VERSION ""

NS_ :

BS_:

BU_: Master ODrive_Axis0 ODrive_Axis1 ODrive_Axis2 ODrive_Axis3 ODrive_Axis4 ODrive_Axis5 ODrive_Axis6 ODrive_Axis7

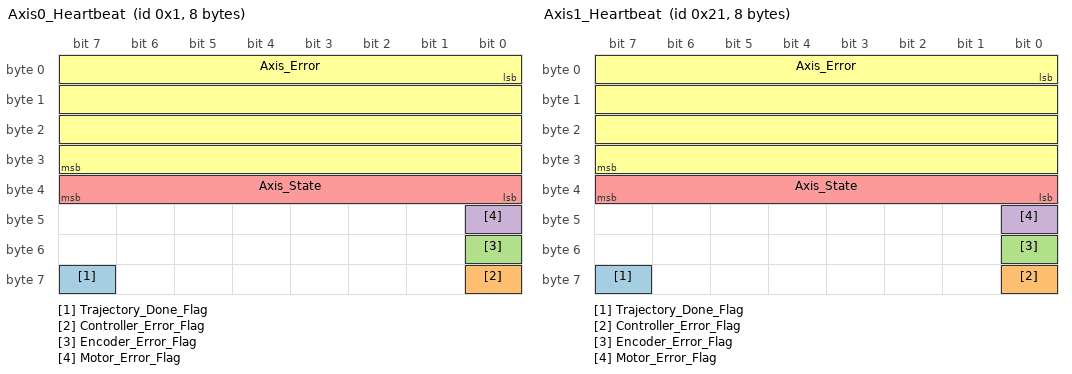
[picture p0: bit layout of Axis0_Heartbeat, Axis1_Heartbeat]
BO_ 1 Axis0_Heartbeat: 8 ODrive_Axis0
 SG_ Trajectory_Done_Flag : 63|1@1+ (1,0) [0|0] ""  Master
 SG_ Controller_Error_Flag : 56|1@1+ (1,0) [0|0] ""  Master
 SG_ Encoder_Error_Flag : 48|1@1+ (1,0) [0|0] ""  Master
 SG_ Motor_Error_Flag : 40|1@1+ (1,0) [0|0] ""  Master
 SG_ Axis_State : 32|8@1+ (1,0) [0|0] ""  Master
 SG_ Axis_Error : 0|32@1+ (1,0) [0|0] ""  Master

BO_ 3 Axis0_Get_Motor_Error: 8 ODrive_Axis0
 SG_ Motor_Error : 0|32@1+ (1,0) [0|0] ""  Master

BO_ 4 Axis0_Get_Encoder_Error: 8 ODrive_Axis0
 SG_ Encoder_Error : 0|32@1+ (1,0) [0|0] ""  Master

BO_ 5 Axis0_Get_Sensorless_Error: 8 ODrive_Axis0
 SG_ Sensorless_Error : 0|32@1+ (1,0) [0|0] ""  Master

BO_ 33 Axis1_Heartbeat: 8 ODrive_Axis1
 SG_ Trajectory_Done_Flag : 63|1@1+ (1,0) [0|0] ""  Master
 SG_ Controller_Error_Flag : 56|1@1+ (1,0) [0|0] ""  Master
 SG_ Encoder_Error_Flag : 48|1@1+ (1,0) [0|0] ""  Master
 SG_ Motor_Error_Flag : 40|1@1+ (1,0) [0|0] ""  Master
 SG_ Axis_State : 32|8@1+ (1,0) [0|0] ""  Master
 SG_ Axis_Error : 0|32@1+ (1,0) [0|0] ""  Master

BO_ 35 Axis1_Get_Motor_Error: 8 ODrive_Axis1
 SG_ Motor_Error : 0|32@1+ (1,0) [0|0] ""  Master

BO_ 36 Axis1_Get_Encoder_Error: 8 ODrive_Axis1
 SG_ Encoder_Error : 0|32@1+ (1,0) [0|0] ""  Master

BO_ 37 Axis1_Get_Sensorless_Error: 8 ODrive_Axis1
 SG_ Sensorless_Error : 0|32@1+ (1,0) [0|0] ""  Master

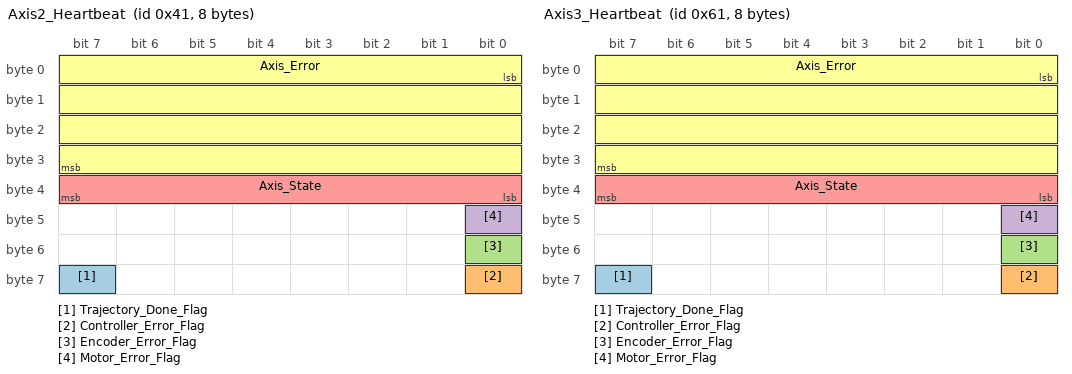
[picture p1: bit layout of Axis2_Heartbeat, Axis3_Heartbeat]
BO_ 65 Axis2_Heartbeat: 8 ODrive_Axis2
 SG_ Trajectory_Done_Flag : 63|1@1+ (1,0) [0|0] ""  Master
 SG_ Controller_Error_Flag : 56|1@1+ (1,0) [0|0] ""  Master
 SG_ Encoder_Error_Flag : 48|1@1+ (1,0) [0|0] ""  Master
 SG_ Motor_Error_Flag : 40|1@1+ (1,0) [0|0] ""  Master
 SG_ Axis_State : 32|8@1+ (1,0) [0|0] ""  Master
 SG_ Axis_Error : 0|32@1+ (1,0) [0|0] ""  Master

BO_ 67 Axis2_Get_Motor_Error: 8 ODrive_Axis2
 SG_ Motor_Error : 0|32@1+ (1,0) [0|0] ""  Master

BO_ 68 Axis2_Get_Encoder_Error: 8 ODrive_Axis2
 SG_ Encoder_Error : 0|32@1+ (1,0) [0|0] ""  Master

BO_ 69 Axis2_Get_Sensorless_Error: 8 ODrive_Axis2
 SG_ Sensorless_Error : 0|32@1+ (1,0) [0|0] ""  Master

BO_ 97 Axis3_Heartbeat: 8 ODrive_Axis3
 SG_ Trajectory_Done_Flag : 63|1@1+ (1,0) [0|0] ""  Master
 SG_ Controller_Error_Flag : 56|1@1+ (1,0) [0|0] ""  Master
 SG_ Encoder_Error_Flag : 48|1@1+ (1,0) [0|0] ""  Master
 SG_ Motor_Error_Flag : 40|1@1+ (1,0) [0|0] ""  Master
 SG_ Axis_State : 32|8@1+ (1,0) [0|0] ""  Master
 SG_ Axis_Error : 0|32@1+ (1,0) [0|0] ""  Master

BO_ 99 Axis3_Get_Motor_Error: 8 ODrive_Axis3
 SG_ Motor_Error : 0|32@1+ (1,0) [0|0] ""  Master

BO_ 100 Axis3_Get_Encoder_Error: 8 ODrive_Axis3
 SG_ Encoder_Error : 0|32@1+ (1,0) [0|0] ""  Master

BO_ 101 Axis3_Get_Sensorless_Error: 8 ODrive_Axis3
 SG_ Sensorless_Error : 0|32@1+ (1,0) [0|0] ""  Master

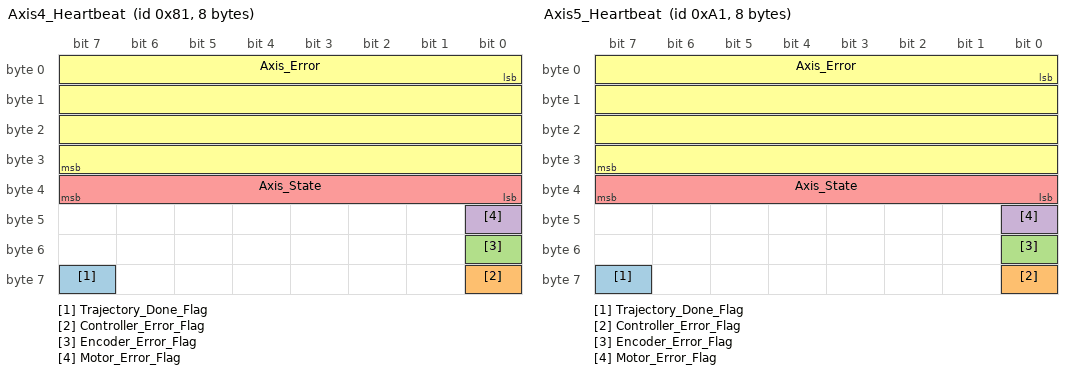
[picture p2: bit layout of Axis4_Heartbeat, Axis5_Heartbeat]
BO_ 129 Axis4_Heartbeat: 8 ODrive_Axis4
 SG_ Trajectory_Done_Flag : 63|1@1+ (1,0) [0|0] ""  Master
 SG_ Controller_Error_Flag : 56|1@1+ (1,0) [0|0] ""  Master
 SG_ Encoder_Error_Flag : 48|1@1+ (1,0) [0|0] ""  Master
 SG_ Motor_Error_Flag : 40|1@1+ (1,0) [0|0] ""  Master
 SG_ Axis_State : 32|8@1+ (1,0) [0|0] ""  Master
 SG_ Axis_Error : 0|32@1+ (1,0) [0|0] ""  Master

BO_ 131 Axis4_Get_Motor_Error: 8 ODrive_Axis4
 SG_ Motor_Error : 0|32@1+ (1,0) [0|0] ""  Master

BO_ 132 Axis4_Get_Encoder_Error: 8 ODrive_Axis4
 SG_ Encoder_Error : 0|32@1+ (1,0) [0|0] ""  Master

BO_ 133 Axis4_Get_Sensorless_Error: 8 ODrive_Axis4
 SG_ Sensorless_Error : 0|32@1+ (1,0) [0|0] ""  Master

BO_ 161 Axis5_Heartbeat: 8 ODrive_Axis5
 SG_ Trajectory_Done_Flag : 63|1@1+ (1,0) [0|0] ""  Master
 SG_ Controller_Error_Flag : 56|1@1+ (1,0) [0|0] ""  Master
 SG_ Encoder_Error_Flag : 48|1@1+ (1,0) [0|0] ""  Master
 SG_ Motor_Error_Flag : 40|1@1+ (1,0) [0|0] ""  Master
 SG_ Axis_State : 32|8@1+ (1,0) [0|0] ""  Master
 SG_ Axis_Error : 0|32@1+ (1,0) [0|0] ""  Master

BO_ 163 Axis5_Get_Motor_Error: 8 ODrive_Axis5
 SG_ Motor_Error : 0|32@1+ (1,0) [0|0] ""  Master

BO_ 164 Axis5_Get_Encoder_Error: 8 ODrive_Axis5
 SG_ Encoder_Error : 0|32@1+ (1,0) [0|0] ""  Master

BO_ 165 Axis5_Get_Sensorless_Error: 8 ODrive_Axis5
 SG_ Sensorless_Error : 0|32@1+ (1,0) [0|0] ""  Master

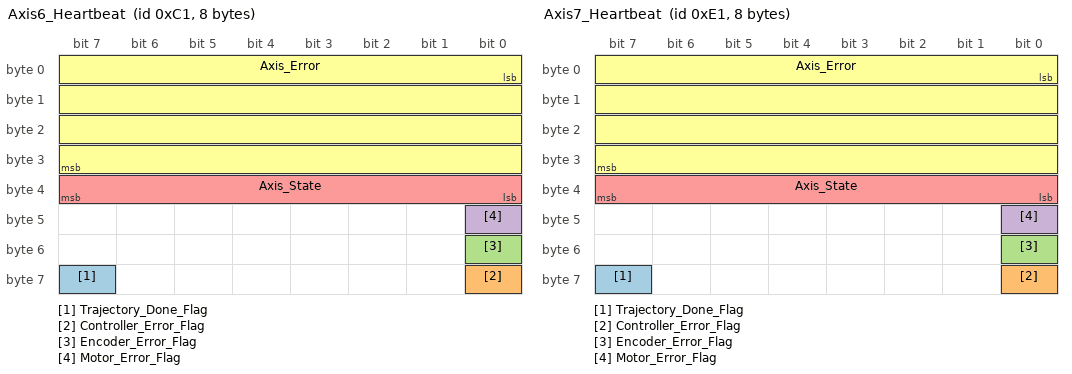
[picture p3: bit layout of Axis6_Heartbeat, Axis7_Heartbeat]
BO_ 193 Axis6_Heartbeat: 8 ODrive_Axis6
 SG_ Trajectory_Done_Flag : 63|1@1+ (1,0) [0|0] ""  Master
 SG_ Controller_Error_Flag : 56|1@1+ (1,0) [0|0] ""  Master
 SG_ Encoder_Error_Flag : 48|1@1+ (1,0) [0|0] ""  Master
 SG_ Motor_Error_Flag : 40|1@1+ (1,0) [0|0] ""  Master
 SG_ Axis_State : 32|8@1+ (1,0) [0|0] ""  Master
 SG_ Axis_Error : 0|32@1+ (1,0) [0|0] ""  Master

BO_ 195 Axis6_Get_Motor_Error: 8 ODrive_Axis6
 SG_ Motor_Error : 0|32@1+ (1,0) [0|0] ""  Master

BO_ 196 Axis6_Get_Encoder_Error: 8 ODrive_Axis6
 SG_ Encoder_Error : 0|32@1+ (1,0) [0|0] ""  Master

BO_ 197 Axis6_Get_Sensorless_Error: 8 ODrive_Axis6
 SG_ Sensorless_Error : 0|32@1+ (1,0) [0|0] ""  Master

BO_ 225 Axis7_Heartbeat: 8 ODrive_Axis7
 SG_ Trajectory_Done_Flag : 63|1@1+ (1,0) [0|0] ""  Master
 SG_ Controller_Error_Flag : 56|1@1+ (1,0) [0|0] ""  Master
 SG_ Encoder_Error_Flag : 48|1@1+ (1,0) [0|0] ""  Master
 SG_ Motor_Error_Flag : 40|1@1+ (1,0) [0|0] ""  Master
 SG_ Axis_State : 32|8@1+ (1,0) [0|0] ""  Master
 SG_ Axis_Error : 0|32@1+ (1,0) [0|0] ""  Master

BO_ 227 Axis7_Get_Motor_Error: 8 ODrive_Axis7
 SG_ Motor_Error : 0|32@1+ (1,0) [0|0] ""  Master

BO_ 228 Axis7_Get_Encoder_Error: 8 ODrive_Axis7
 SG_ Encoder_Error : 0|32@1+ (1,0) [0|0] ""  Master

BO_ 229 Axis7_Get_Sensorless_Error: 8 ODrive_Axis7
 SG_ Sensorless_Error : 0|32@1+ (1,0) [0|0] ""  Master

CM_ BU_ Master "Master node comment";
CM_ BU_ ODrive_Axis0 "Axis node 0 comment";
CM_ BU_ ODrive_Axis1 "Axis node 1 comment";
CM_ BU_ ODrive_Axis2 "Axis node 2 comment";
CM_ BU_ ODrive_Axis3 "Axis node 3 comment";
CM_ BU_ ODrive_Axis4 "Axis node 4 comment";
CM_ BU_ ODrive_Axis5 "Axis node 5 comment";
CM_ BU_ ODrive_Axis6 "Axis node 6 comment";
CM_ BU_ ODrive_Axis7 "Axis node 7 comment";

VAL_ 1 Axis_State 0 "UNDEFINED" 1 "IDLE" 2 "STARTUP_SEQUENCE" 3 "FULL_CALIBRATION_SEQUENCE" 4 "MOTOR_CALIBRATION" 6 "ENCODER_INDEX_SEARCH" 7 "ENCODER_OFFSET_CALIBRATION" 8 "CLOSED_LOOP_CONTROL" 9 "LOCKIN_SPIN" 10 "ENCODER_DIR_FIND" 11 "HOMING" 12 "ENCODER_HALL_POLARITY_CALIBRATION" 13 "ENCODER_HALL_PHASE_CALIBRATION" ;
VAL_ 1 Axis_Error 0 "NONE" 1 "INVALID_STATE" 64 "MOTOR_FAILED" 128 "SENSORLESS_ESTIMATOR_FAILED" 256 "ENCODER_FAILED" 512 "CONTROLLER_FAILED" 2048 "WATCHDOG_TIMER_EXPIRED" 4096 "MIN_ENDSTOP_PRESSED" 8192 "MAX_ENDSTOP_PRESSED" 16384 "ESTOP_REQUESTED" 131072 "HOMING_WITHOUT_ENDSTOP" 262144 "OVER_TEMP" 524288 "UNKNOWN_POSITION" ;
VAL_ 3 Motor_Error 0 "NONE" 1 "PHASE_RESISTANCE_OUT_OF_RANGE" 2 "PHASE_INDUCTANCE_OUT_OF_RANGE" 8 "DRV_FAULT" 16 "CONTROL_DEADLINE_MISSED" 128 "MODULATION_MAGNITUDE" 1024 "CURRENT_SENSE_SATURATION" 4096 "CURRENT_LIMIT_VIOLATION" 65536 "MODULATION_IS_NAN" 131072 "MOTOR_THERMISTOR_OVER_TEMP" 262144 "FET_THERMISTOR_OVER_TEMP" 524288 "TIMER_UPDATE_MISSED" 1048576 "CURRENT_MEASUREMENT_UNAVAILABLE" 2097152 "CONTROLLER_FAILED" 4194304 "I_BUS_OUT_OF_RANGE" 8388608 "BRAKE_RESISTOR_DISARMED" 16777216 "SYSTEM_LEVEL" 33554432 "BAD_TIMING" 67108864 "UNKNOWN_PHASE_ESTIMATE" 134217728 "UNKNOWN_PHASE_VEL" 268435456 "UNKNOWN_TORQUE" 536870912 "UNKNOWN_CURRENT_COMMAND" 1073741824 "UNKNOWN_CURRENT_MEASUREMENT" 2147483648 "UNKNOWN_VBUS_VOLTAGE" 4294967296 "UNKNOWN_VOLTAGE_COMMAND" 8589934592 "UNKNOWN_GAINS" 17179869184 "CONTROLLER_INITIALIZING" 34359738368 "UNBALANCED_PHASES" ;
VAL_ 4 Encoder_Error 0 "NONE" 1 "UNSTABLE_GAIN" 2 "CPR_POLEPAIRS_MISMATCH" 4 "NO_RESPONSE" 8 "UNSUPPORTED_ENCODER_MODE" 16 "ILLEGAL_HALL_STATE" 32 "INDEX_NOT_FOUND_YET" 64 "ABS_SPI_TIMEOUT" 128 "ABS_SPI_COM_FAIL" 256 "ABS_SPI_NOT_READY" 512 "HALL_NOT_CALIBRATED_YET" ;
VAL_ 5 Sensorless_Error 0 "NONE" 1 "UNSTABLE_GAIN" 2 "UNKNOWN_CURRENT_MEASUREMENT" ;
VAL_ 33 Axis_State 0 "UNDEFINED" 1 "IDLE" 2 "STARTUP_SEQUENCE" 3 "FULL_CALIBRATION_SEQUENCE" 4 "MOTOR_CALIBRATION" 6 "ENCODER_INDEX_SEARCH" 7 "ENCODER_OFFSET_CALIBRATION" 8 "CLOSED_LOOP_CONTROL" 9 "LOCKIN_SPIN" 10 "ENCODER_DIR_FIND" 11 "HOMING" 12 "ENCODER_HALL_POLARITY_CALIBRATION" 13 "ENCODER_HALL_PHASE_CALIBRATION" ;
VAL_ 33 Axis_Error 0 "NONE" 1 "INVALID_STATE" 64 "MOTOR_FAILED" 128 "SENSORLESS_ESTIMATOR_FAILED" 256 "ENCODER_FAILED" 512 "CONTROLLER_FAILED" 2048 "WATCHDOG_TIMER_EXPIRED" 4096 "MIN_ENDSTOP_PRESSED" 8192 "MAX_ENDSTOP_PRESSED" 16384 "ESTOP_REQUESTED" 131072 "HOMING_WITHOUT_ENDSTOP" 262144 "OVER_TEMP" 524288 "UNKNOWN_POSITION" ;
VAL_ 35 Motor_Error 0 "NONE" 1 "PHASE_RESISTANCE_OUT_OF_RANGE" 2 "PHASE_INDUCTANCE_OUT_OF_RANGE" 8 "DRV_FAULT" 16 "CONTROL_DEADLINE_MISSED" 128 "MODULATION_MAGNITUDE" 1024 "CURRENT_SENSE_SATURATION" 4096 "CURRENT_LIMIT_VIOLATION" 65536 "MODULATION_IS_NAN" 131072 "MOTOR_THERMISTOR_OVER_TEMP" 262144 "FET_THERMISTOR_OVER_TEMP" 524288 "TIMER_UPDATE_MISSED" 1048576 "CURRENT_MEASUREMENT_UNAVAILABLE" 2097152 "CONTROLLER_FAILED" 4194304 "I_BUS_OUT_OF_RANGE" 8388608 "BRAKE_RESISTOR_DISARMED" 16777216 "SYSTEM_LEVEL" 33554432 "BAD_TIMING" 67108864 "UNKNOWN_PHASE_ESTIMATE" 134217728 "UNKNOWN_PHASE_VEL" 268435456 "UNKNOWN_TORQUE" 536870912 "UNKNOWN_CURRENT_COMMAND" 1073741824 "UNKNOWN_CURRENT_MEASUREMENT" 2147483648 "UNKNOWN_VBUS_VOLTAGE" 4294967296 "UNKNOWN_VOLTAGE_COMMAND" 8589934592 "UNKNOWN_GAINS" 17179869184 "CONTROLLER_INITIALIZING" 34359738368 "UNBALANCED_PHASES" ;
VAL_ 36 Encoder_Error 0 "NONE" 1 "UNSTABLE_GAIN" 2 "CPR_POLEPAIRS_MISMATCH" 4 "NO_RESPONSE" 8 "UNSUPPORTED_ENCODER_MODE" 16 "ILLEGAL_HALL_STATE" 32 "INDEX_NOT_FOUND_YET" 64 "ABS_SPI_TIMEOUT" 128 "ABS_SPI_COM_FAIL" 256 "ABS_SPI_NOT_READY" 512 "HALL_NOT_CALIBRATED_YET" ;
VAL_ 37 Sensorless_Error 0 "NONE" 1 "UNSTABLE_GAIN" 2 "UNKNOWN_CURRENT_MEASUREMENT" ;
VAL_ 65 Axis_State 0 "UNDEFINED" 1 "IDLE" 2 "STARTUP_SEQUENCE" 3 "FULL_CALIBRATION_SEQUENCE" 4 "MOTOR_CALIBRATION" 6 "ENCODER_INDEX_SEARCH" 7 "ENCODER_OFFSET_CALIBRATION" 8 "CLOSED_LOOP_CONTROL" 9 "LOCKIN_SPIN" 10 "ENCODER_DIR_FIND" 11 "HOMING" 12 "ENCODER_HALL_POLARITY_CALIBRATION" 13 "ENCODER_HALL_PHASE_CALIBRATION" ;
VAL_ 65 Axis_Error 0 "NONE" 1 "INVALID_STATE" 64 "MOTOR_FAILED" 128 "SENSORLESS_ESTIMATOR_FAILED" 256 "ENCODER_FAILED" 512 "CONTROLLER_FAILED" 2048 "WATCHDOG_TIMER_EXPIRED" 4096 "MIN_ENDSTOP_PRESSED" 8192 "MAX_ENDSTOP_PRESSED" 16384 "ESTOP_REQUESTED" 131072 "HOMING_WITHOUT_ENDSTOP" 262144 "OVER_TEMP" 524288 "UNKNOWN_POSITION" ;
VAL_ 67 Motor_Error 0 "NONE" 1 "PHASE_RESISTANCE_OUT_OF_RANGE" 2 "PHASE_INDUCTANCE_OUT_OF_RANGE" 8 "DRV_FAULT" 16 "CONTROL_DEADLINE_MISSED" 128 "MODULATION_MAGNITUDE" 1024 "CURRENT_SENSE_SATURATION" 4096 "CURRENT_LIMIT_VIOLATION" 65536 "MODULATION_IS_NAN" 131072 "MOTOR_THERMISTOR_OVER_TEMP" 262144 "FET_THERMISTOR_OVER_TEMP" 524288 "TIMER_UPDATE_MISSED" 1048576 "CURRENT_MEASUREMENT_UNAVAILABLE" 2097152 "CONTROLLER_FAILED" 4194304 "I_BUS_OUT_OF_RANGE" 8388608 "BRAKE_RESISTOR_DISARMED" 16777216 "SYSTEM_LEVEL" 33554432 "BAD_TIMING" 67108864 "UNKNOWN_PHASE_ESTIMATE" 134217728 "UNKNOWN_PHASE_VEL" 268435456 "UNKNOWN_TORQUE" 536870912 "UNKNOWN_CURRENT_COMMAND" 1073741824 "UNKNOWN_CURRENT_MEASUREMENT" 2147483648 "UNKNOWN_VBUS_VOLTAGE" 4294967296 "UNKNOWN_VOLTAGE_COMMAND" 8589934592 "UNKNOWN_GAINS" 17179869184 "CONTROLLER_INITIALIZING" 34359738368 "UNBALANCED_PHASES" ;
VAL_ 68 Encoder_Error 0 "NONE" 1 "UNSTABLE_GAIN" 2 "CPR_POLEPAIRS_MISMATCH" 4 "NO_RESPONSE" 8 "UNSUPPORTED_ENCODER_MODE" 16 "ILLEGAL_HALL_STATE" 32 "INDEX_NOT_FOUND_YET" 64 "ABS_SPI_TIMEOUT" 128 "ABS_SPI_COM_FAIL" 256 "ABS_SPI_NOT_READY" 512 "HALL_NOT_CALIBRATED_YET" ;
VAL_ 69 Sensorless_Error 0 "NONE" 1 "UNSTABLE_GAIN" 2 "UNKNOWN_CURRENT_MEASUREMENT" ;
VAL_ 97 Axis_State 0 "UNDEFINED" 1 "IDLE" 2 "STARTUP_SEQUENCE" 3 "FULL_CALIBRATION_SEQUENCE" 4 "MOTOR_CALIBRATION" 6 "ENCODER_INDEX_SEARCH" 7 "ENCODER_OFFSET_CALIBRATION" 8 "CLOSED_LOOP_CONTROL" 9 "LOCKIN_SPIN" 10 "ENCODER_DIR_FIND" 11 "HOMING" 12 "ENCODER_HALL_POLARITY_CALIBRATION" 13 "ENCODER_HALL_PHASE_CALIBRATION" ;
VAL_ 97 Axis_Error 0 "NONE" 1 "INVALID_STATE" 64 "MOTOR_FAILED" 128 "SENSORLESS_ESTIMATOR_FAILED" 256 "ENCODER_FAILED" 512 "CONTROLLER_FAILED" 2048 "WATCHDOG_TIMER_EXPIRED" 4096 "MIN_ENDSTOP_PRESSED" 8192 "MAX_ENDSTOP_PRESSED" 16384 "ESTOP_REQUESTED" 131072 "HOMING_WITHOUT_ENDSTOP" 262144 "OVER_TEMP" 524288 "UNKNOWN_POSITION" ;
VAL_ 99 Motor_Error 0 "NONE" 1 "PHASE_RESISTANCE_OUT_OF_RANGE" 2 "PHASE_INDUCTANCE_OUT_OF_RANGE" 8 "DRV_FAULT" 16 "CONTROL_DEADLINE_MISSED" 128 "MODULATION_MAGNITUDE" 1024 "CURRENT_SENSE_SATURATION" 4096 "CURRENT_LIMIT_VIOLATION" 65536 "MODULATION_IS_NAN" 131072 "MOTOR_THERMISTOR_OVER_TEMP" 262144 "FET_THERMISTOR_OVER_TEMP" 524288 "TIMER_UPDATE_MISSED" 1048576 "CURRENT_MEASUREMENT_UNAVAILABLE" 2097152 "CONTROLLER_FAILED" 4194304 "I_BUS_OUT_OF_RANGE" 8388608 "BRAKE_RESISTOR_DISARMED" 16777216 "SYSTEM_LEVEL" 33554432 "BAD_TIMING" 67108864 "UNKNOWN_PHASE_ESTIMATE" 134217728 "UNKNOWN_PHASE_VEL" 268435456 "UNKNOWN_TORQUE" 536870912 "UNKNOWN_CURRENT_COMMAND" 1073741824 "UNKNOWN_CURRENT_MEASUREMENT" 2147483648 "UNKNOWN_VBUS_VOLTAGE" 4294967296 "UNKNOWN_VOLTAGE_COMMAND" 8589934592 "UNKNOWN_GAINS" 17179869184 "CONTROLLER_INITIALIZING" 34359738368 "UNBALANCED_PHASES" ;
VAL_ 100 Encoder_Error 0 "NONE" 1 "UNSTABLE_GAIN" 2 "CPR_POLEPAIRS_MISMATCH" 4 "NO_RESPONSE" 8 "UNSUPPORTED_ENCODER_MODE" 16 "ILLEGAL_HALL_STATE" 32 "INDEX_NOT_FOUND_YET" 64 "ABS_SPI_TIMEOUT" 128 "ABS_SPI_COM_FAIL" 256 "ABS_SPI_NOT_READY" 512 "HALL_NOT_CALIBRATED_YET" ;
VAL_ 101 Sensorless_Error 0 "NONE" 1 "UNSTABLE_GAIN" 2 "UNKNOWN_CURRENT_MEASUREMENT" ;
VAL_ 129 Axis_State 0 "UNDEFINED" 1 "IDLE" 2 "STARTUP_SEQUENCE" 3 "FULL_CALIBRATION_SEQUENCE" 4 "MOTOR_CALIBRATION" 6 "ENCODER_INDEX_SEARCH" 7 "ENCODER_OFFSET_CALIBRATION" 8 "CLOSED_LOOP_CONTROL" 9 "LOCKIN_SPIN" 10 "ENCODER_DIR_FIND" 11 "HOMING" 12 "ENCODER_HALL_POLARITY_CALIBRATION" 13 "ENCODER_HALL_PHASE_CALIBRATION" ;
VAL_ 129 Axis_Error 0 "NONE" 1 "INVALID_STATE" 64 "MOTOR_FAILED" 128 "SENSORLESS_ESTIMATOR_FAILED" 256 "ENCODER_FAILED" 512 "CONTROLLER_FAILED" 2048 "WATCHDOG_TIMER_EXPIRED" 4096 "MIN_ENDSTOP_PRESSED" 8192 "MAX_ENDSTOP_PRESSED" 16384 "ESTOP_REQUESTED" 131072 "HOMING_WITHOUT_ENDSTOP" 262144 "OVER_TEMP" 524288 "UNKNOWN_POSITION" ;
VAL_ 131 Motor_Error 0 "NONE" 1 "PHASE_RESISTANCE_OUT_OF_RANGE" 2 "PHASE_INDUCTANCE_OUT_OF_RANGE" 8 "DRV_FAULT" 16 "CONTROL_DEADLINE_MISSED" 128 "MODULATION_MAGNITUDE" 1024 "CURRENT_SENSE_SATURATION" 4096 "CURRENT_LIMIT_VIOLATION" 65536 "MODULATION_IS_NAN" 131072 "MOTOR_THERMISTOR_OVER_TEMP" 262144 "FET_THERMISTOR_OVER_TEMP" 524288 "TIMER_UPDATE_MISSED" 1048576 "CURRENT_MEASUREMENT_UNAVAILABLE" 2097152 "CONTROLLER_FAILED" 4194304 "I_BUS_OUT_OF_RANGE" 8388608 "BRAKE_RESISTOR_DISARMED" 16777216 "SYSTEM_LEVEL" 33554432 "BAD_TIMING" 67108864 "UNKNOWN_PHASE_ESTIMATE" 134217728 "UNKNOWN_PHASE_VEL" 268435456 "UNKNOWN_TORQUE" 536870912 "UNKNOWN_CURRENT_COMMAND" 1073741824 "UNKNOWN_CURRENT_MEASUREMENT" 2147483648 "UNKNOWN_VBUS_VOLTAGE" 4294967296 "UNKNOWN_VOLTAGE_COMMAND" 8589934592 "UNKNOWN_GAINS" 17179869184 "CONTROLLER_INITIALIZING" 34359738368 "UNBALANCED_PHASES" ;
VAL_ 132 Encoder_Error 0 "NONE" 1 "UNSTABLE_GAIN" 2 "CPR_POLEPAIRS_MISMATCH" 4 "NO_RESPONSE" 8 "UNSUPPORTED_ENCODER_MODE" 16 "ILLEGAL_HALL_STATE" 32 "INDEX_NOT_FOUND_YET" 64 "ABS_SPI_TIMEOUT" 128 "ABS_SPI_COM_FAIL" 256 "ABS_SPI_NOT_READY" 512 "HALL_NOT_CALIBRATED_YET" ;
VAL_ 133 Sensorless_Error 0 "NONE" 1 "UNSTABLE_GAIN" 2 "UNKNOWN_CURRENT_MEASUREMENT" ;
VAL_ 161 Axis_State 0 "UNDEFINED" 1 "IDLE" 2 "STARTUP_SEQUENCE" 3 "FULL_CALIBRATION_SEQUENCE" 4 "MOTOR_CALIBRATION" 6 "ENCODER_INDEX_SEARCH" 7 "ENCODER_OFFSET_CALIBRATION" 8 "CLOSED_LOOP_CONTROL" 9 "LOCKIN_SPIN" 10 "ENCODER_DIR_FIND" 11 "HOMING" 12 "ENCODER_HALL_POLARITY_CALIBRATION" 13 "ENCODER_HALL_PHASE_CALIBRATION" ;
VAL_ 161 Axis_Error 0 "NONE" 1 "INVALID_STATE" 64 "MOTOR_FAILED" 128 "SENSORLESS_ESTIMATOR_FAILED" 256 "ENCODER_FAILED" 512 "CONTROLLER_FAILED" 2048 "WATCHDOG_TIMER_EXPIRED" 4096 "MIN_ENDSTOP_PRESSED" 8192 "MAX_ENDSTOP_PRESSED" 16384 "ESTOP_REQUESTED" 131072 "HOMING_WITHOUT_ENDSTOP" 262144 "OVER_TEMP" 524288 "UNKNOWN_POSITION" ;
VAL_ 163 Motor_Error 0 "NONE" 1 "PHASE_RESISTANCE_OUT_OF_RANGE" 2 "PHASE_INDUCTANCE_OUT_OF_RANGE" 8 "DRV_FAULT" 16 "CONTROL_DEADLINE_MISSED" 128 "MODULATION_MAGNITUDE" 1024 "CURRENT_SENSE_SATURATION" 4096 "CURRENT_LIMIT_VIOLATION" 65536 "MODULATION_IS_NAN" 131072 "MOTOR_THERMISTOR_OVER_TEMP" 262144 "FET_THERMISTOR_OVER_TEMP" 524288 "TIMER_UPDATE_MISSED" 1048576 "CURRENT_MEASUREMENT_UNAVAILABLE" 2097152 "CONTROLLER_FAILED" 4194304 "I_BUS_OUT_OF_RANGE" 8388608 "BRAKE_RESISTOR_DISARMED" 16777216 "SYSTEM_LEVEL" 33554432 "BAD_TIMING" 67108864 "UNKNOWN_PHASE_ESTIMATE" 134217728 "UNKNOWN_PHASE_VEL" 268435456 "UNKNOWN_TORQUE" 536870912 "UNKNOWN_CURRENT_COMMAND" 1073741824 "UNKNOWN_CURRENT_MEASUREMENT" 2147483648 "UNKNOWN_VBUS_VOLTAGE" 4294967296 "UNKNOWN_VOLTAGE_COMMAND" 8589934592 "UNKNOWN_GAINS" 17179869184 "CONTROLLER_INITIALIZING" 34359738368 "UNBALANCED_PHASES" ;
VAL_ 164 Encoder_Error 0 "NONE" 1 "UNSTABLE_GAIN" 2 "CPR_POLEPAIRS_MISMATCH" 4 "NO_RESPONSE" 8 "UNSUPPORTED_ENCODER_MODE" 16 "ILLEGAL_HALL_STATE" 32 "INDEX_NOT_FOUND_YET" 64 "ABS_SPI_TIMEOUT" 128 "ABS_SPI_COM_FAIL" 256 "ABS_SPI_NOT_READY" 512 "HALL_NOT_CALIBRATED_YET" ;
VAL_ 165 Sensorless_Error 0 "NONE" 1 "UNSTABLE_GAIN" 2 "UNKNOWN_CURRENT_MEASUREMENT" ;
VAL_ 193 Axis_State 0 "UNDEFINED" 1 "IDLE" 2 "STARTUP_SEQUENCE" 3 "FULL_CALIBRATION_SEQUENCE" 4 "MOTOR_CALIBRATION" 6 "ENCODER_INDEX_SEARCH" 7 "ENCODER_OFFSET_CALIBRATION" 8 "CLOSED_LOOP_CONTROL" 9 "LOCKIN_SPIN" 10 "ENCODER_DIR_FIND" 11 "HOMING" 12 "ENCODER_HALL_POLARITY_CALIBRATION" 13 "ENCODER_HALL_PHASE_CALIBRATION" ;
VAL_ 193 Axis_Error 0 "NONE" 1 "INVALID_STATE" 64 "MOTOR_FAILED" 128 "SENSORLESS_ESTIMATOR_FAILED" 256 "ENCODER_FAILED" 512 "CONTROLLER_FAILED" 2048 "WATCHDOG_TIMER_EXPIRED" 4096 "MIN_ENDSTOP_PRESSED" 8192 "MAX_ENDSTOP_PRESSED" 16384 "ESTOP_REQUESTED" 131072 "HOMING_WITHOUT_ENDSTOP" 262144 "OVER_TEMP" 524288 "UNKNOWN_POSITION" ;
VAL_ 195 Motor_Error 0 "NONE" 1 "PHASE_RESISTANCE_OUT_OF_RANGE" 2 "PHASE_INDUCTANCE_OUT_OF_RANGE" 8 "DRV_FAULT" 16 "CONTROL_DEADLINE_MISSED" 128 "MODULATION_MAGNITUDE" 1024 "CURRENT_SENSE_SATURATION" 4096 "CURRENT_LIMIT_VIOLATION" 65536 "MODULATION_IS_NAN" 131072 "MOTOR_THERMISTOR_OVER_TEMP" 262144 "FET_THERMISTOR_OVER_TEMP" 524288 "TIMER_UPDATE_MISSED" 1048576 "CURRENT_MEASUREMENT_UNAVAILABLE" 2097152 "CONTROLLER_FAILED" 4194304 "I_BUS_OUT_OF_RANGE" 8388608 "BRAKE_RESISTOR_DISARMED" 16777216 "SYSTEM_LEVEL" 33554432 "BAD_TIMING" 67108864 "UNKNOWN_PHASE_ESTIMATE" 134217728 "UNKNOWN_PHASE_VEL" 268435456 "UNKNOWN_TORQUE" 536870912 "UNKNOWN_CURRENT_COMMAND" 1073741824 "UNKNOWN_CURRENT_MEASUREMENT" 2147483648 "UNKNOWN_VBUS_VOLTAGE" 4294967296 "UNKNOWN_VOLTAGE_COMMAND" 8589934592 "UNKNOWN_GAINS" 17179869184 "CONTROLLER_INITIALIZING" 34359738368 "UNBALANCED_PHASES" ;
VAL_ 196 Encoder_Error 0 "NONE" 1 "UNSTABLE_GAIN" 2 "CPR_POLEPAIRS_MISMATCH" 4 "NO_RESPONSE" 8 "UNSUPPORTED_ENCODER_MODE" 16 "ILLEGAL_HALL_STATE" 32 "INDEX_NOT_FOUND_YET" 64 "ABS_SPI_TIMEOUT" 128 "ABS_SPI_COM_FAIL" 256 "ABS_SPI_NOT_READY" 512 "HALL_NOT_CALIBRATED_YET" ;
VAL_ 197 Sensorless_Error 0 "NONE" 1 "UNSTABLE_GAIN" 2 "UNKNOWN_CURRENT_MEASUREMENT" ;
VAL_ 225 Axis_State 0 "UNDEFINED" 1 "IDLE" 2 "STARTUP_SEQUENCE" 3 "FULL_CALIBRATION_SEQUENCE" 4 "MOTOR_CALIBRATION" 6 "ENCODER_INDEX_SEARCH" 7 "ENCODER_OFFSET_CALIBRATION" 8 "CLOSED_LOOP_CONTROL" 9 "LOCKIN_SPIN" 10 "ENCODER_DIR_FIND" 11 "HOMING" 12 "ENCODER_HALL_POLARITY_CALIBRATION" 13 "ENCODER_HALL_PHASE_CALIBRATION" ;
VAL_ 225 Axis_Error 0 "NONE" 1 "INVALID_STATE" 64 "MOTOR_FAILED" 128 "SENSORLESS_ESTIMATOR_FAILED" 256 "ENCODER_FAILED" 512 "CONTROLLER_FAILED" 2048 "WATCHDOG_TIMER_EXPIRED" 4096 "MIN_ENDSTOP_PRESSED" 8192 "MAX_ENDSTOP_PRESSED" 16384 "ESTOP_REQUESTED" 131072 "HOMING_WITHOUT_ENDSTOP" 262144 "OVER_TEMP" 524288 "UNKNOWN_POSITION" ;
VAL_ 227 Motor_Error 0 "NONE" 1 "PHASE_RESISTANCE_OUT_OF_RANGE" 2 "PHASE_INDUCTANCE_OUT_OF_RANGE" 8 "DRV_FAULT" 16 "CONTROL_DEADLINE_MISSED" 128 "MODULATION_MAGNITUDE" 1024 "CURRENT_SENSE_SATURATION" 4096 "CURRENT_LIMIT_VIOLATION" 65536 "MODULATION_IS_NAN" 131072 "MOTOR_THERMISTOR_OVER_TEMP" 262144 "FET_THERMISTOR_OVER_TEMP" 524288 "TIMER_UPDATE_MISSED" 1048576 "CURRENT_MEASUREMENT_UNAVAILABLE" 2097152 "CONTROLLER_FAILED" 4194304 "I_BUS_OUT_OF_RANGE" 8388608 "BRAKE_RESISTOR_DISARMED" 16777216 "SYSTEM_LEVEL" 33554432 "BAD_TIMING" 67108864 "UNKNOWN_PHASE_ESTIMATE" 134217728 "UNKNOWN_PHASE_VEL" 268435456 "UNKNOWN_TORQUE" 536870912 "UNKNOWN_CURRENT_COMMAND" 1073741824 "UNKNOWN_CURRENT_MEASUREMENT" 2147483648 "UNKNOWN_VBUS_VOLTAGE" 4294967296 "UNKNOWN_VOLTAGE_COMMAND" 8589934592 "UNKNOWN_GAINS" 17179869184 "CONTROLLER_INITIALIZING" 34359738368 "UNBALANCED_PHASES" ;
VAL_ 228 Encoder_Error 0 "NONE" 1 "UNSTABLE_GAIN" 2 "CPR_POLEPAIRS_MISMATCH" 4 "NO_RESPONSE" 8 "UNSUPPORTED_ENCODER_MODE" 16 "ILLEGAL_HALL_STATE" 32 "INDEX_NOT_FOUND_YET" 64 "ABS_SPI_TIMEOUT" 128 "ABS_SPI_COM_FAIL" 256 "ABS_SPI_NOT_READY" 512 "HALL_NOT_CALIBRATED_YET" ;
VAL_ 229 Sensorless_Error 0 "NONE" 1 "UNSTABLE_GAIN" 2 "UNKNOWN_CURRENT_MEASUREMENT" ;
